VERSION ""

NS_ :

BS_:
BU_: CAN_PDM1
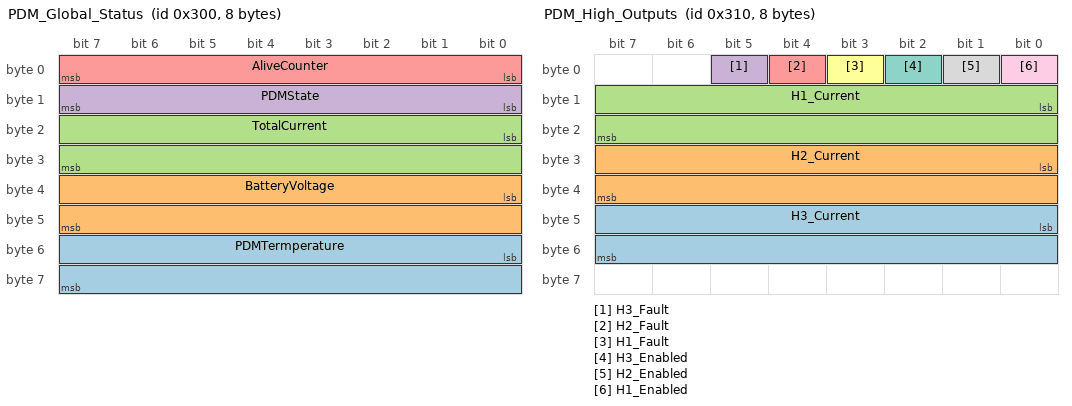
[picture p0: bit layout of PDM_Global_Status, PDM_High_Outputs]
BO_ 768 PDM_Global_Status: 8 CAN_PDM1
   SG_ PDMTermperature : 48|16@1+ (0.01,0) [0|655.35] "C" CAN_PDM1
   SG_ BatteryVoltage : 32|16@1+ (0.01,0) [0|655.35] "V" CAN_PDM1
   SG_ TotalCurrent : 16|16@1+ (0.1,0) [0|6553.5] "A" CAN_PDM1
   SG_ PDMState : 8|8@1+ (1,0) [0|255] "" CAN_PDM1
   SG_ AliveCounter : 0|8@1+ (1,0) [0|255] "" CAN_PDM1

BO_ 784 PDM_High_Outputs: 8 CAN_PDM1
   SG_ H3_Current : 40|16@1+ (1,0) [0|65535] "A" CAN_PDM1
   SG_ H2_Current : 24|16@1+ (0.1,0) [0|6553.5] "A" CAN_PDM1
   SG_ H1_Current : 8|16@1+ (0.1,0) [0|6553.5] "A" CAN_PDM1
   SG_ H3_Fault : 5|1@1- (1,0) [0|1] "" CAN_PDM1
   SG_ H2_Fault : 4|1@1- (1,0) [0|1] "" CAN_PDM1
   SG_ H1_Fault : 3|1@1- (1,0) [0|1] "" CAN_PDM1
   SG_ H3_Enabled : 2|1@1- (1,0) [0|1] "" CAN_PDM1
   SG_ H2_Enabled : 1|1@1- (1,0) [0|1] "" CAN_PDM1
   SG_ H1_Enabled : 0|1@1- (1,0) [0|1] "" CAN_PDM1

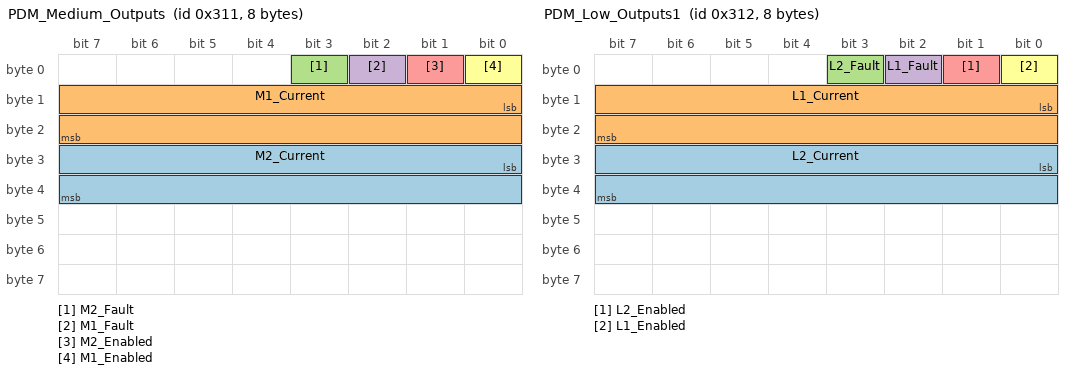
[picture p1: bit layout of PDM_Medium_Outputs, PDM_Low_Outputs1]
BO_ 785 PDM_Medium_Outputs: 8 CAN_PDM1
   SG_ M2_Current : 24|16@1+ (0.1,0) [0|6553.5] "A" CAN_PDM1
   SG_ M1_Current : 8|16@1+ (0.1,0) [0|6553.5] "A" CAN_PDM1
   SG_ M2_Fault : 3|1@1- (1,0) [0|1] "" CAN_PDM1
   SG_ M1_Fault : 2|1@1- (1,0) [0|1] "" CAN_PDM1
   SG_ M2_Enabled : 1|1@1- (1,0) [0|1] "" CAN_PDM1
   SG_ M1_Enabled : 0|1@1- (1,0) [0|1] "" CAN_PDM1

BO_ 786 PDM_Low_Outputs1: 8 CAN_PDM1
   SG_ L2_Current : 24|16@1+ (0.1,0) [0|6553.5] "A" CAN_PDM1
   SG_ L1_Current : 8|16@1+ (0.1,0) [0|6553.5] "A" CAN_PDM1
   SG_ L2_Fault : 3|1@1- (1,0) [0|1] "" CAN_PDM1
   SG_ L1_Fault : 2|1@1- (1,0) [0|1] "" CAN_PDM1
   SG_ L2_Enabled : 1|1@1- (1,0) [0|1] "" CAN_PDM1
   SG_ L1_Enabled : 0|1@1- (1,0) [0|1] "" CAN_PDM1

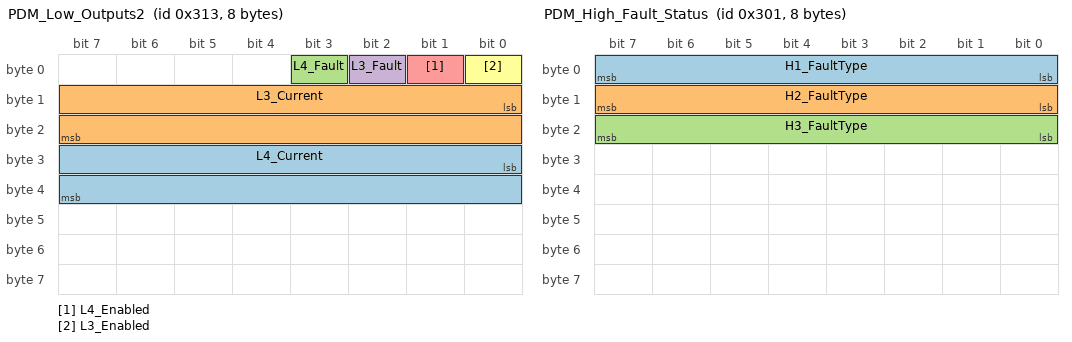
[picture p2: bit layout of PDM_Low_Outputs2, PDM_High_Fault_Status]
BO_ 787 PDM_Low_Outputs2: 8 CAN_PDM1
   SG_ L4_Current : 24|16@1+ (0.1,0) [0|6553.5] "A" CAN_PDM1
   SG_ L3_Current : 8|16@1+ (0.1,0) [0|6553.5] "A" CAN_PDM1
   SG_ L4_Fault : 3|1@1- (1,0) [0|1] "" CAN_PDM1
   SG_ L3_Fault : 2|1@1- (1,0) [0|1] "" CAN_PDM1
   SG_ L4_Enabled : 1|1@1- (1,0) [0|1] "" CAN_PDM1
   SG_ L3_Enabled : 0|1@1- (1,0) [0|1] "" CAN_PDM1

BO_ 769 PDM_High_Fault_Status: 8 CAN_PDM1
   SG_ H1_FaultType : 0|8@1+ (1,0) [0|255] "" Vector__XXX
   SG_ H2_FaultType : 8|8@1+ (1,0) [0|1] "" Vector__XXX
   SG_ H3_FaultType : 23|8@0+ (1,0) [0|1] "" Vector__XXX

BO_ 770 PDM_Medium_Fault_Status: 8 CAN_PDM1
   SG_ M1_FaultType : 0|8@1+ (1,0) [0|255] "" CAN_PDM1
   SG_ M2_FaultType : 8|8@1+ (1,0) [0|255] "" CAN_PDM1

BO_ 771 PDM_LOW1_Status: 8 CAN_PDM1
   SG_ L1_FaultType : 0|8@1+ (1,0) [0|255] "" CAN_PDM1
   SG_ L2_FaultType : 8|8@1+ (1,0) [0|255] "" CAN_PDM1

BO_ 772 PDM_LOW2_Status: 8 CAN_PDM1
   SG_ L3_FaultType : 0|8@1+ (1,0) [0|8] "" CAN_PDM1
   SG_ L4_FaultType : 0|8@1+ (1,0) [0|8] "" CAN_PDM1

BA_DEF_ BO_ "GenMsgBackgroundColor" STRING ;
BA_DEF_ BO_ "GenMsgForegroundColor" STRING ;
BA_DEF_ BO_ "labelfilters" INT 0 0;
BA_DEF_DEF_ "GenMsgBackgroundColor" "#ffffff";
BA_DEF_DEF_ "GenMsgForegroundColor" "#000000";
BA_DEF_DEF_ "labelfilters" 1;
CM_ BU_ CAN_PDM1 "Default node if none specified";
VAL_ 768 PDMState 0 "INIT" 1 "RUN" 2 "FAULT" 3 "OVERTEMP" 4 "UNDERVOLTAGE" 5 "SLEEP";
VAL_ 769 H1_FaultType 0 "NONE" 1 "OVERCURRENT" 2 "SHORT_CIRCUIT" 3 "OPEN_LOAD" 4 "THERMAL" 5 "UNDERVOLTAGE";
VAL_ 769 H2_FaultType 0 "NONE" 1 "OVERCURRENT" 2 "SHORT_CIRCUIT" 3 "OPEN_LOAD" 4 "THERMAL" 5 "UNDERVOLTAGE";
VAL_ 769 H3_FaultType 0 "NONE" 1 "OVERCURRENT" 2 "SHORT_CIRCUIT" 3 "OPEN_LOAD" 4 "THERMAL" 5 "UNDERVOLTAGE" 0 "No Description";
VAL_ 770 M1_FaultType 0 "NONE" 1 "OVERCURRENT" 2 "SHORT_CIRCUIT" 3 "OPEN_LOAD" 4 "THERMAL" 5 "UNDERVOLTAGE";
VAL_ 770 M2_FaultType 0 "NONE" 1 "OVERCURRENT" 2 "SHORT_CIRCUIT" 3 "OPEN_LOAD" 4 "THERMAL" 5 "UNDERVOLTAGE";
VAL_ 771 L1_FaultType 0 "NONE" 1 "OVERCURRENT" 2 "SHORT_CIRCUIT" 3 "OPEN_LOAD" 4 "THERMAL" 5 "UNDERVOLTAGE";
VAL_ 771 L2_FaultType 0 "NONE" 1 "OVERCURRENT" 2 "SHORT_CIRCUIT" 3 "OPEN_LOAD" 4 "THERMAL" 5 "UNDERVOLTAGE";
VAL_ 772 L3_FaultType 0 "NONE" 1 "OVERCURRENT" 2 "SHORTCIRCUIT" 3 "OPEN_LOAD" 4 "THERMAL" 5 "UNDERVOLTAGE";
VAL_ 772 L4_FaultType 0 "NONE" 1 "OVERCURRENT" 2 "SHORTCIRCUIT" 3 "OPEN_LOAD" 4 "THERMAL" 5 "UNDERVOLTAGE";
